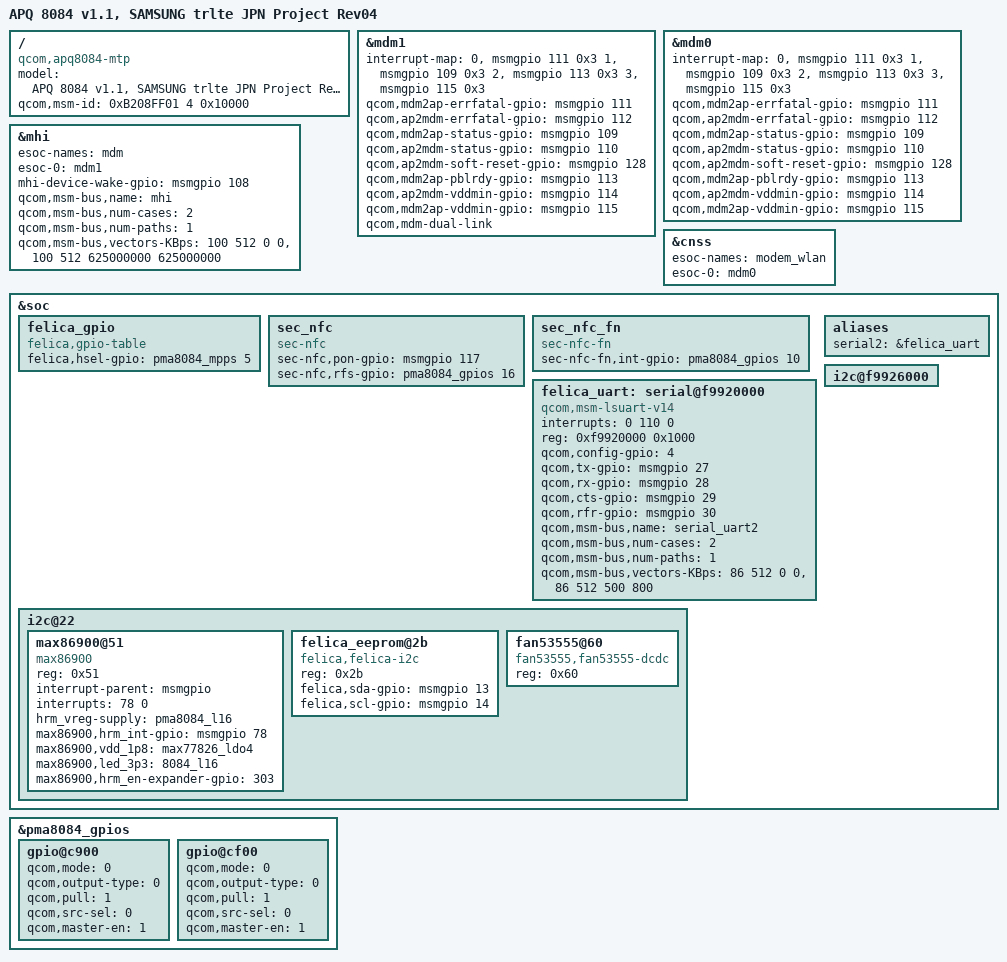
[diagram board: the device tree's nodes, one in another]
/* Copyright (c) 2013-2014, The Linux Foundation. All rights reserved.
 *
 * This program is free software; you can redistribute it and/or modify
 * it under the terms of the GNU General Public License version 2 and
 * only version 2 as published by the Free Software Foundation.
 *
 * This program is distributed in the hope that it will be useful,
 * but WITHOUT ANY WARRANTY; without even the implied warranty of
 * MERCHANTABILITY or FITNESS FOR A PARTICULAR PURPOSE.  See the
 * GNU General Public License for more details.
 */

/dts-v1/;

/memreserve/ 0x00000000 0x00001000;

#include "apq8084-v1.1.dtsi"
#include "apq8084-mtp.dtsi"

#include "apq8084-sii8620-mhl3-trlte-r04.dtsi"
#include "apq8084-sec-trlte-r04.dtsi"
#include "apq8084-sec-trlte-battery-r04.dtsi"
#include "apq8084-sec-isdb-trlte-r01.dtsi"
/ {
	model = "APQ 8084 v1.1, SAMSUNG trlte JPN Project Rev04";
	compatible = "qcom,apq8084-mtp", "qcom,apq8084", "qcom,mtp";
    qcom,msm-id = <0xB208FF01 4 0x10000>;
    /* [31:24] chip-id, [23:16] platform-id, [15:8] national code, [7:0] operator revision, reserved */
};

&mdm1 {
	interrupt-map = <0 &msmgpio 111 0x3
			1 &msmgpio 109 0x3
			2 &msmgpio 113 0x3
			3 &msmgpio 115 0x3>;
	qcom,mdm2ap-errfatal-gpio = <&msmgpio 111 0x00>;
	qcom,ap2mdm-errfatal-gpio = <&msmgpio 112 0x00>;
	qcom,mdm2ap-status-gpio   = <&msmgpio 109 0x00>;
	qcom,ap2mdm-status-gpio   = <&msmgpio 110 0x00>;
	qcom,ap2mdm-soft-reset-gpio = <&msmgpio 128 0x00>;
	qcom,mdm2ap-pblrdy-gpio = <&msmgpio 113 0x00>;
	qcom,ap2mdm-vddmin-gpio = <&msmgpio 114 0x00>;
	qcom,mdm2ap-vddmin-gpio = <&msmgpio 115 0x00>;
	qcom,mdm-dual-link;
	status = "ok";
};

&mdm0 {
	interrupt-map = <0 &msmgpio 111 0x3
			1 &msmgpio 109 0x3
			2 &msmgpio 113 0x3
			3 &msmgpio 115 0x3>;
	qcom,mdm2ap-errfatal-gpio = <&msmgpio 111 0x00>;
	qcom,ap2mdm-errfatal-gpio = <&msmgpio 112 0x00>;
	qcom,mdm2ap-status-gpio   = <&msmgpio 109 0x00>;
	qcom,ap2mdm-status-gpio   = <&msmgpio 110 0x00>;
	qcom,ap2mdm-soft-reset-gpio = <&msmgpio 128 0x00>;
	qcom,mdm2ap-pblrdy-gpio = <&msmgpio 113 0x00>;
	qcom,ap2mdm-vddmin-gpio = <&msmgpio 114 0x00>;
	qcom,mdm2ap-vddmin-gpio = <&msmgpio 115 0x00>;
	status = "ok";
};

&mhi {
	esoc-names = "mdm";
	esoc-0 = <&mdm1>;
	mhi-device-wake-gpio =
		<&msmgpio 108 0>;
	qcom,msm-bus,name = "mhi";
	qcom,msm-bus,num-cases = <2>;
	qcom,msm-bus,num-paths = <1>;
	qcom,msm-bus,vectors-KBps =
		<100 512 0 0>,
		<100 512 625000000 625000000>;
};

&cnss {
	esoc-names = "modem_wlan";
	esoc-0 = <&mdm0>;
};

/* JPN System: JPN model specific overriding configuration */

&soc {
	/* CONFIG_FELICA changes start */
	felica_gpio
	{
		compatible = "felica,gpio-table";
		felica,hsel-gpio = 	<&pma8084_mpps 5 0x00>;
	};
	
	sec_nfc
	{
		compatible = "sec-nfc";
		sec-nfc,pon-gpio = 	<&msmgpio 117 0x00>;
		sec-nfc,rfs-gpio = 	<&pma8084_gpios 16 0x00>;
	};

	sec_nfc_fn
	{
		compatible = "sec-nfc-fn";
		sec-nfc-fn,int-gpio = 	<&pma8084_gpios 10 0x00>;
	};

	/* NEED TO CHANGE THE FOLLOWING DEVICE ENTRY */
	felica_uart: serial@f9920000 
	{
		compatible = "qcom,msm-lsuart-v14";
		interrupts = <0 110 0>;
		reg = <0xf9920000 0x1000>;
		status = "ok";
		
		qcom,config-gpio = <4>;
		qcom,tx-gpio = <&msmgpio 27 0x00>;
		qcom,rx-gpio = <&msmgpio 28 0x00>;
		qcom,cts-gpio = <&msmgpio 29 0x00>;
		qcom,rfr-gpio = <&msmgpio 30 0x00>;
		qcom,msm-bus,name = "serial_uart2";
		qcom,msm-bus,num-cases = <2>;
		qcom,msm-bus,num-paths = <1>;
		qcom,msm-bus,vectors-KBps =
		<86 512 0 0>,
		<86 512 500 800>;
	};

	aliases {
		serial2 = &felica_uart;
	};
	/* CONFIG_FELICA changes end */

	i2c@f9926000 { /* BLSP1 QUP4 */
		/delete-node/ sec-nfc@27;
		/delete-node/ max86900@51;
		/delete-node/ fan53555@60;
	};

	i2c@22 {
		max86900@51 {
			compatible = "max86900";
			reg = <0x51>;
			interrupt-parent = <&msmgpio>;
			interrupts = <78 0>;
			hrm_vreg-supply = <&pma8084_l16>;
			max86900,hrm_int-gpio = <&msmgpio 78 0x00>;
			max86900,vdd_1p8 = "max77826_ldo4";
			max86900,led_3p3 = "8084_l16";
			max86900,hrm_en-expander-gpio = <303>;
		};

		/* CONFIG_FELICA changes START */
		felica_eeprom@2b {
			compatible = "felica,felica-i2c";
			reg = <0x2b>;
			felica,sda-gpio = <&msmgpio 13 0>;
			felica,scl-gpio = <&msmgpio 14 0>;
		};
		/* CONFIG_FELICA changes END */

		fan53555@60 {
			compatible = "fan53555,fan53555-dcdc";
			reg = <0x60>;
		};
	};
};

&pma8084_gpios {
	gpio@c900 { /* GPIO 10 */
		/* FeliCa INT */
		qcom,mode = <0>;		/* Digital Input */
		qcom,output-type = <0>;	/* CMOS logic */		
		qcom,pull = <1>;
		qcom,src-sel = <0>;		/* GPIO */
		qcom,master-en = <1>;	/* Enable GPIO */
	};

	gpio@cf00 { /* GPIO 16 */
		/* FeliCa INTU */
		qcom,mode = <0>;		/* Digital input*/
		qcom,output-type = <0>;	/* CMOS logic */	
		qcom,pull = <1>;		
		qcom,src-sel = <0>;		/* GPIO */
		qcom,master-en = <1>;		/* Enable GPIO */
	};
};
